# MSS_PCR2 register map
Vendor: Texas Instruments
Peripheral module from a debugger description file (folder awr2544).
Registers are 32-bit, read-write, no defined reset value unless marked. A register's access mark holds for its fields unless they carry their own. Offsets are as the file gives them; lines under a group give offsets from that group; [hi:lo] are bit positions; {n}, {i} and the like mark numbered series; 'fields as' and 'values as' point back to an identical list; <NAME> marks a mode.

## MSS_PCR2 (part 1 of 2)
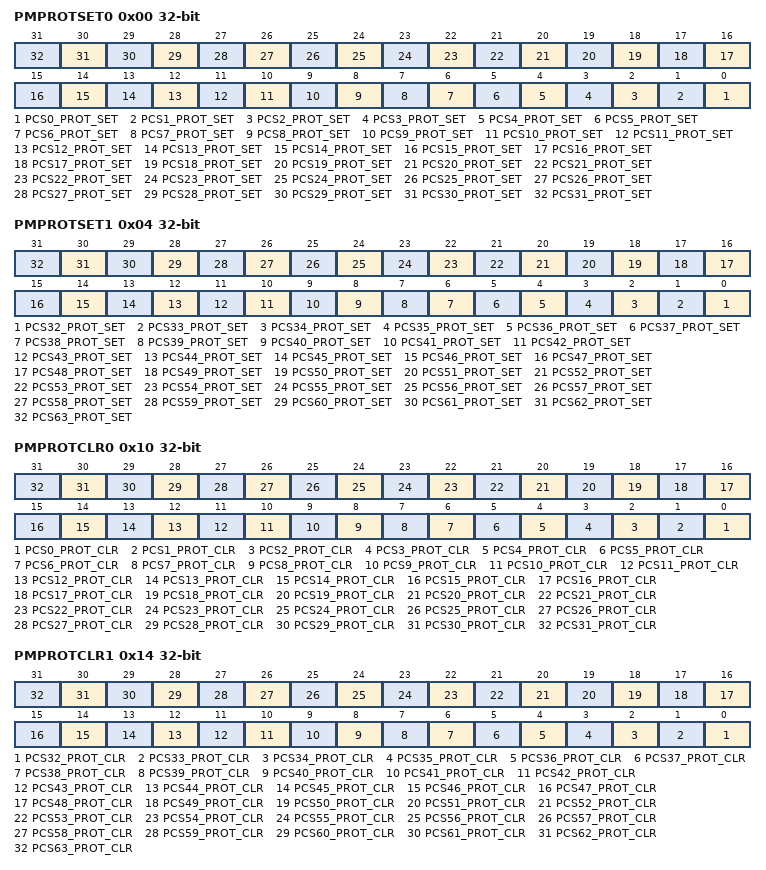
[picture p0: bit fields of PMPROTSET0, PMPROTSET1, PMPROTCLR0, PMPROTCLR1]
0x00 PMPROTSET0 — Set-only register to protect PCS frames 0 to 31
  [n] PCS{n}_PROT_SET (n=0..31) — Readable in user and privileged modes 1 = The corresponding peripheral memory frame can be written to only in privileged mode but can be read in both user and privileged modes. 0 = The corresponding peripheral memory frame can be written to and read from in both user and privileged modes. Writable only in privileged mode 1 = Sets the corresponding bit in PMPROTSET0 and PMPROTCLR0 registers 0 = Has no effect Only those bits which have a slave at the corresponding bit position are implemented. Hence, the size of this register is device dependent. Writes to unimplemented bits have no effect and reads yield 0.
0x04 PMPROTSET1 — Set-only register to protect PCS frames 32 to 63
  [n-32] PCS{n}_PROT_SET (n=32..63) — Readable in user and privileged modes 1 = The corresponding peripheral memory frame can be written to only in privileged mode but can be read in both user and privileged modes. 0 = The corresponding peripheral memory frame can be written to and read from in both user and privileged modes. Writable only in privileged mode 1 = Sets the corresponding bit in PMPROTSET1 and PMPROTCLR1 registers 0 = Has no effect
0x10 PMPROTCLR0 — Clear-only register to protect PCS frames 0 to 31
  [n] PCS{n}_PROT_CLR (n=0..31) — Readable in user and privileged modes 1 = The corresponding peripheral memory frame can be written to only in privileged mode but can be read in both user and privileged modes. 0 = The corresponding peripheral memory frame can be written to and read from in both user and privileged modes. Writable only in privileged mode 1 = Clears the corresponding bit in PMPROTCLR0 and PMPROTSET0 registers 0 = Has no effect
0x14 PMPROTCLR1 — Clear-only register to protect PCS frames 32 to 63
  [n-32] PCS{n}_PROT_CLR (n=32..63) — Readable in user and privileged modes 1 = The corresponding peripheral memory frame can be written to only in privileged mode but can be read in both user and privileged modes. 0 = The corresponding peripheral memory frame can be written to and read from in both user and privileged modes. Writable only in privileged mode 1 = Clears the corresponding bit in PMPROTCLR1 and PMPROTSET1 registers 0 = Has no effect
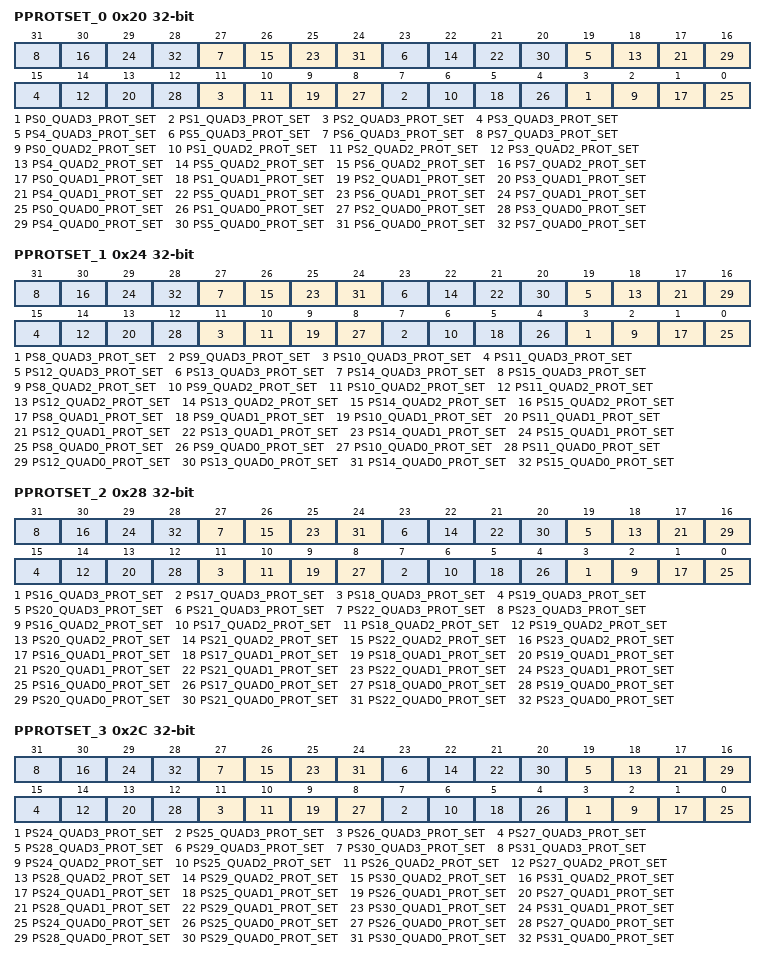
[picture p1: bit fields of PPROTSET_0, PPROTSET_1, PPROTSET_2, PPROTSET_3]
0x20 PPROTSET_0 — Set-only register to protect the 32 quadrants of PS0 to PS7
  [4n+3] PS{n}_QUAD3_PROT_SET (n=0..7) — Readable in both user and privileged modes. 1 = The quadrant ‘m’ of the peripheral frame ‘n’ can be written to only in privileged mode but can be read in both user and privileged modes. 0 = The corresponding peripheral memory frame can be written to and read from in both user and privileged modes. Writable only in privileged mode 1 = Sets the corresponding bit in PPROTSET0 and PPROTCLR0 registers 0 = Has no effect
  [4n+2] PS{n}_QUAD2_PROT_SET (n=0..7) — Readable in both user and privileged modes. 1 = The quadrant ‘m’ of the peripheral frame ‘n’ can be written to only in privileged mode but can be read in both user and privileged modes. 0 = The corresponding peripheral memory frame can be written to and read from in both user and privileged modes. Writable only in privileged mode 1 = Sets the corresponding bit in PPROTSET0 and PPROTCLR0 registers 0 = Has no effect
  [4n+1] PS{n}_QUAD1_PROT_SET (n=0..7) — Readable in both user and privileged modes. 1 = The quadrant ‘m’ of the peripheral frame ‘n’ can be written to only in privileged mode but can be read in both user and privileged modes. 0 = The corresponding peripheral memory frame can be written to and read from in both user and privileged modes. Writable only in privileged mode 1 = Sets the corresponding bit in PPROTSET0 and PPROTCLR0 registers 0 = Has no effect
  [4n] PS{n}_QUAD0_PROT_SET (n=0..7) — Readable in both user and privileged modes. 1 = The quadrant ‘m’ of the peripheral frame ‘n’ can be written to only in privileged mode but can be read in both user and privileged modes. 0 = The corresponding peripheral memory frame can be written to and read from in both user and privileged modes. Writable only in privileged mode 1 = Sets the corresponding bit in PPROTSET0 and PPROTCLR0 registers 0 = Has no effect
0x24 PPROTSET_1 — Set-only register to protect the 32 quadrants of PS8 to PS15
  [4n-29] PS{n}_QUAD3_PROT_SET (n=8..15) — Readable in both user and privileged modes. 1 = The quadrant ‘m’ of the peripheral frame ‘n’ can be written to only in privileged mode but can be read in both user and privileged modes. 0 = The corresponding peripheral memory frame can be written to and read from in both user and privileged modes. Writable only in privileged mode 1 = Sets the corresponding bit in PPROTSET1 and PPROTCLR1 registers 0 = Has no effect
  [4n-30] PS{n}_QUAD2_PROT_SET (n=8..15) — Readable in both user and privileged modes. 1 = The quadrant ‘m’ of the peripheral frame ‘n’ can be written to only in privileged mode but can be read in both user and privileged modes. 0 = The corresponding peripheral memory frame can be written to and read from in both user and privileged modes. Writable only in privileged mode 1 = Sets the corresponding bit in PPROTSET1 and PPROTCLR1 registers 0 = Has no effect
  [4n-31] PS{n}_QUAD1_PROT_SET (n=8..15) — Readable in both user and privileged modes. 1 = The quadrant ‘m’ of the peripheral frame ‘n’ can be written to only in privileged mode but can be read in both user and privileged modes. 0 = The corresponding peripheral memory frame can be written to and read from in both user and privileged modes. Writable only in privileged mode 1 = Sets the corresponding bit in PPROTSET1 and PPROTCLR1 registers 0 = Has no effect
  [4n-32] PS{n}_QUAD0_PROT_SET (n=8..15) — Readable in both user and privileged modes. 1 = The quadrant ‘m’ of the peripheral frame ‘n’ can be written to only in privileged mode but can be read in both user and privileged modes. 0 = The corresponding peripheral memory frame can be written to and read from in both user and privileged modes. Writable only in privileged mode 1 = Sets the corresponding bit in PPROTSET1 and PPROTCLR1 registers 0 = Has no effect
0x28 PPROTSET_2 — Set-only register to protect the 32 quadrants of PS16 to PS23
  [4n-61] PS{n}_QUAD3_PROT_SET (n=16..23) — Readable in both user and privileged modes. 1 = The quadrant ‘m’ of the peripheral frame ‘n’ can be written to only in privileged mode but can be read in both user and privileged modes. 0 = The corresponding peripheral memory frame can be written to and read from in both user and privileged modes. Writable only in privileged mode 1 = Sets the corresponding bit in PPROTSET2 and PPROTCLR2 registers 0 = Has no effect
  [4n-62] PS{n}_QUAD2_PROT_SET (n=16..23) — Readable in both user and privileged modes. 1 = The quadrant ‘m’ of the peripheral frame ‘n’ can be written to only in privileged mode but can be read in both user and privileged modes. 0 = The corresponding peripheral memory frame can be written to and read from in both user and privileged modes. Writable only in privileged mode 1 = Sets the corresponding bit in PPROTSET2 and PPROTCLR2 registers 0 = Has no effect
  [4n-63] PS{n}_QUAD1_PROT_SET (n=16..23) — Readable in both user and privileged modes. 1 = The quadrant ‘m’ of the peripheral frame ‘n’ can be written to only in privileged mode but can be read in both user and privileged modes. 0 = The corresponding peripheral memory frame can be written to and read from in both user and privileged modes. Writable only in privileged mode 1 = Sets the corresponding bit in PPROTSET2 and PPROTCLR2 registers 0 = Has no effect
  [4n-64] PS{n}_QUAD0_PROT_SET (n=16..23) — Readable in both user and privileged modes. 1 = The quadrant ‘m’ of the peripheral frame ‘n’ can be written to only in privileged mode but can be read in both user and privileged modes. 0 = The corresponding peripheral memory frame can be written to and read from in both user and privileged modes. Writable only in privileged mode 1 = Sets the corresponding bit in PPROTSET2 and PPROTCLR2 registers 0 = Has no effect
0x2C PPROTSET_3 — Set-only register to protect the 32 quadrants of PS24 to PS31
  [4n-93] PS{n}_QUAD3_PROT_SET (n=24..31) — Readable in both user and privileged modes. 1 = The quadrant ‘m’ of the peripheral frame ‘n’ can be written to only in privileged mode but can be read in both user and privileged modes. 0 = The corresponding peripheral memory frame can be written to and read from in both user and privileged modes. Writable only in privileged mode 1 = Sets the corresponding bit in PPROTSET3 and PPROTCLR3 registers 0 = Has no effect
  [4n-94] PS{n}_QUAD2_PROT_SET (n=24..31) — Readable in both user and privileged modes. 1 = The quadrant ‘m’ of the peripheral frame ‘n’ can be written to only in privileged mode but can be read in both user and privileged modes. 0 = The corresponding peripheral memory frame can be written to and read from in both user and privileged modes. Writable only in privileged mode 1 = Sets the corresponding bit in PPROTSET3 and PPROTCLR3 registers 0 = Has no effect
  [4n-95] PS{n}_QUAD1_PROT_SET (n=24..31) — Readable in both user and privileged modes. 1 = The quadrant ‘m’ of the peripheral frame ‘n’ can be written to only in privileged mode but can be read in both user and privileged modes. 0 = The corresponding peripheral memory frame can be written to and read from in both user and privileged modes. Writable only in privileged mode 1 = Sets the corresponding bit in PPROTSET3 and PPROTCLR3 registers 0 = Has no effect
  [4n-96] PS{n}_QUAD0_PROT_SET (n=24..31) — Readable in both user and privileged modes. 1 = The quadrant ‘m’ of the peripheral frame ‘n’ can be written to only in privileged mode but can be read in both user and privileged modes. 0 = The corresponding peripheral memory frame can be written to and read from in both user and privileged modes. Writable only in privileged mode 1 = Sets the corresponding bit in PPROTSET3 and PPROTCLR3 registers 0 = Has no effect
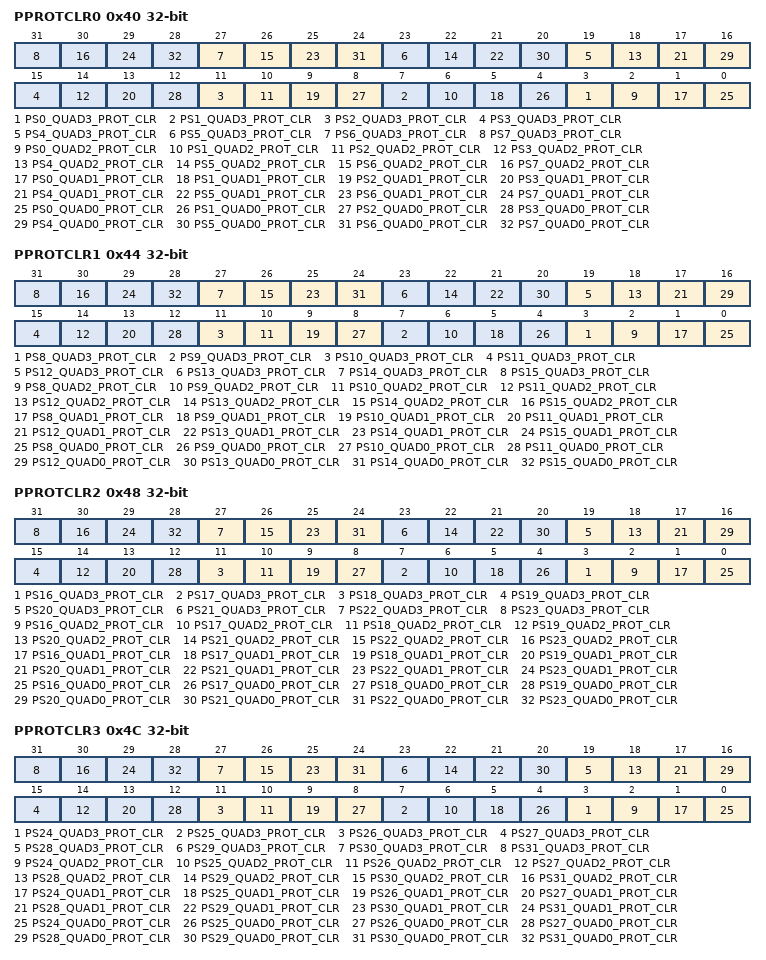
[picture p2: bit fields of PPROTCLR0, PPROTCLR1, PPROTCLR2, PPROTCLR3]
0x40 PPROTCLR0 — Clear-only register to protect the 32 quadrants of PS0 to PS7
  [4n+3] PS{n}_QUAD3_PROT_CLR (n=0..7) — Readable in both user and privileged modes. 1 = The quadrant ‘m’ of the peripheral frame ‘n’ can be written to only in privileged mode but can be read in both user and privileged modes. 0 = The corresponding peripheral memory frame can be written to and read from in both user and privileged modes. Writable only in privileged mode 1 = Clears the corresponding bit in PPROTSET0 and PPROTCLR0 registers 0 = Has no effect
  [4n+2] PS{n}_QUAD2_PROT_CLR (n=0..7) — Readable in both user and privileged modes. 1 = The quadrant ‘m’ of the peripheral frame ‘n’ can be written to only in privileged mode but can be read in both user and privileged modes. 0 = The corresponding peripheral memory frame can be written to and read from in both user and privileged modes. Writable only in privileged mode 1 = Clears the corresponding bit in PPROTSET0 and PPROTCLR0 registers 0 = Has no effect
  [4n+1] PS{n}_QUAD1_PROT_CLR (n=0..7) — Readable in both user and privileged modes. 1 = The quadrant ‘m’ of the peripheral frame ‘n’ can be written to only in privileged mode but can be read in both user and privileged modes. 0 = The corresponding peripheral memory frame can be written to and read from in both user and privileged modes. Writable only in privileged mode 1 = Clears the corresponding bit in PPROTSET0 and PPROTCLR0 registers 0 = Has no effect
  [4n] PS{n}_QUAD0_PROT_CLR (n=0..7) — Readable in both user and privileged modes. 1 = The quadrant ‘m’ of the peripheral frame ‘n’ can be written to only in privileged mode but can be read in both user and privileged modes. 0 = The corresponding peripheral memory frame can be written to and read from in both user and privileged modes. Writable only in privileged mode 1 = Clears the corresponding bit in PPROTSET0 and PPROTCLR0 registers 0 = Has no effect
0x44 PPROTCLR1 — Clear-only register to protect the 32 quadrants of PS8 to PS15
  [4n-29] PS{n}_QUAD3_PROT_CLR (n=8..15) — Readable in both user and privileged modes. 1 = The quadrant ‘m’ of the peripheral frame ‘n’ can be written to only in privileged mode but can be read in both user and privileged modes. 0 = The corresponding peripheral memory frame can be written to and read from in both user and privileged modes. Writable only in privileged mode 1 = Clears the corresponding bit in PPROTSET1 and PPROTCLR1 registers 0 = Has no effect
  [4n-30] PS{n}_QUAD2_PROT_CLR (n=8..15) — Readable in both user and privileged modes. 1 = The quadrant ‘m’ of the peripheral frame ‘n’ can be written to only in privileged mode but can be read in both user and privileged modes. 0 = The corresponding peripheral memory frame can be written to and read from in both user and privileged modes. Writable only in privileged mode 1 = Clears the corresponding bit in PPROTSET1 and PPROTCLR1 registers 0 = Has no effect
  [4n-31] PS{n}_QUAD1_PROT_CLR (n=8..15) — Readable in both user and privileged modes. 1 = The quadrant ‘m’ of the peripheral frame ‘n’ can be written to only in privileged mode but can be read in both user and privileged modes. 0 = The corresponding peripheral memory frame can be written to and read from in both user and privileged modes. Writable only in privileged mode 1 = Clears the corresponding bit in PPROTSET1 and PPROTCLR1 registers 0 = Has no effect
  [4n-32] PS{n}_QUAD0_PROT_CLR (n=8..15) — Readable in both user and privileged modes. 1 = The quadrant ‘m’ of the peripheral frame ‘n’ can be written to only in privileged mode but can be read in both user and privileged modes. 0 = The corresponding peripheral memory frame can be written to and read from in both user and privileged modes. Writable only in privileged mode 1 = Clears the corresponding bit in PPROTSET1 and PPROTCLR1 registers 0 = Has no effect
0x48 PPROTCLR2 — Clear-only register to protect the 32 quadrants of PS16 to PS23
  [4n-61] PS{n}_QUAD3_PROT_CLR (n=16..23) — Readable in both user and privileged modes. 1 = The quadrant ‘m’ of the peripheral frame ‘n’ can be written to only in privileged mode but can be read in both user and privileged modes. 0 = The corresponding peripheral memory frame can be written to and read from in both user and privileged modes. Writable only in privileged mode 1 = Clears the corresponding bit in PPROTSET2 and PPROTCLR2 registers 0 = Has no effect
  [4n-62] PS{n}_QUAD2_PROT_CLR (n=16..23) — Readable in both user and privileged modes. 1 = The quadrant ‘m’ of the peripheral frame ‘n’ can be written to only in privileged mode but can be read in both user and privileged modes. 0 = The corresponding peripheral memory frame can be written to and read from in both user and privileged modes. Writable only in privileged mode 1 = Clears the corresponding bit in PPROTSET2 and PPROTCLR2 registers 0 = Has no effect
  [4n-63] PS{n}_QUAD1_PROT_CLR (n=16..23) — Readable in both user and privileged modes. 1 = The quadrant ‘m’ of the peripheral frame ‘n’ can be written to only in privileged mode but can be read in both user and privileged modes. 0 = The corresponding peripheral memory frame can be written to and read from in both user and privileged modes. Writable only in privileged mode 1 = Clears the corresponding bit in PPROTSET2 and PPROTCLR2 registers 0 = Has no effect
  [4n-64] PS{n}_QUAD0_PROT_CLR (n=16..23) — Readable in both user and privileged modes. 1 = The quadrant ‘m’ of the peripheral frame ‘n’ can be written to only in privileged mode but can be read in both user and privileged modes. 0 = The corresponding peripheral memory frame can be written to and read from in both user and privileged modes. Writable only in privileged mode 1 = Clears the corresponding bit in PPROTSET2 and PPROTCLR2 registers 0 = Has no effect
0x4C PPROTCLR3 — Clear-only register to protect the 32 quadrants of PS24 to PS31
  [4n-93] PS{n}_QUAD3_PROT_CLR (n=24..31) — Readable in both user and privileged modes. 1 = The quadrant ‘m’ of the peripheral frame ‘n’ can be written to only in privileged mode but can be read in both user and privileged modes. 0 = The corresponding peripheral memory frame can be written to and read from in both user and privileged modes. Writable only in privileged mode 1 = Clears the corresponding bit in PPROTSET3 and PPROTCLR3 registers 0 = Has no effect
  [4n-94] PS{n}_QUAD2_PROT_CLR (n=24..31) — Readable in both user and privileged modes. 1 = The quadrant ‘m’ of the peripheral frame ‘n’ can be written to only in privileged mode but can be read in both user and privileged modes. 0 = The corresponding peripheral memory frame can be written to and read from in both user and privileged modes. Writable only in privileged mode 1 = Clears the corresponding bit in PPROTSET3 and PPROTCLR3 registers 0 = Has no effect
  [4n-95] PS{n}_QUAD1_PROT_CLR (n=24..31) — Readable in both user and privileged modes. 1 = The quadrant ‘m’ of the peripheral frame ‘n’ can be written to only in privileged mode but can be read in both user and privileged modes. 0 = The corresponding peripheral memory frame can be written to and read from in both user and privileged modes. Writable only in privileged mode 1 = Clears the corresponding bit in PPROTSET3 and PPROTCLR3 registers 0 = Has no effect
  [4n-96] PS{n}_QUAD0_PROT_CLR (n=24..31) — Readable in both user and privileged modes. 1 = The quadrant ‘m’ of the peripheral frame ‘n’ can be written to only in privileged mode but can be read in both user and privileged modes. 0 = The corresponding peripheral memory frame can be written to and read from in both user and privileged modes. Writable only in privileged mode 1 = Clears the corresponding bit in PPROTSET3 and PPROTCLR3 registers 0 = Has no effect
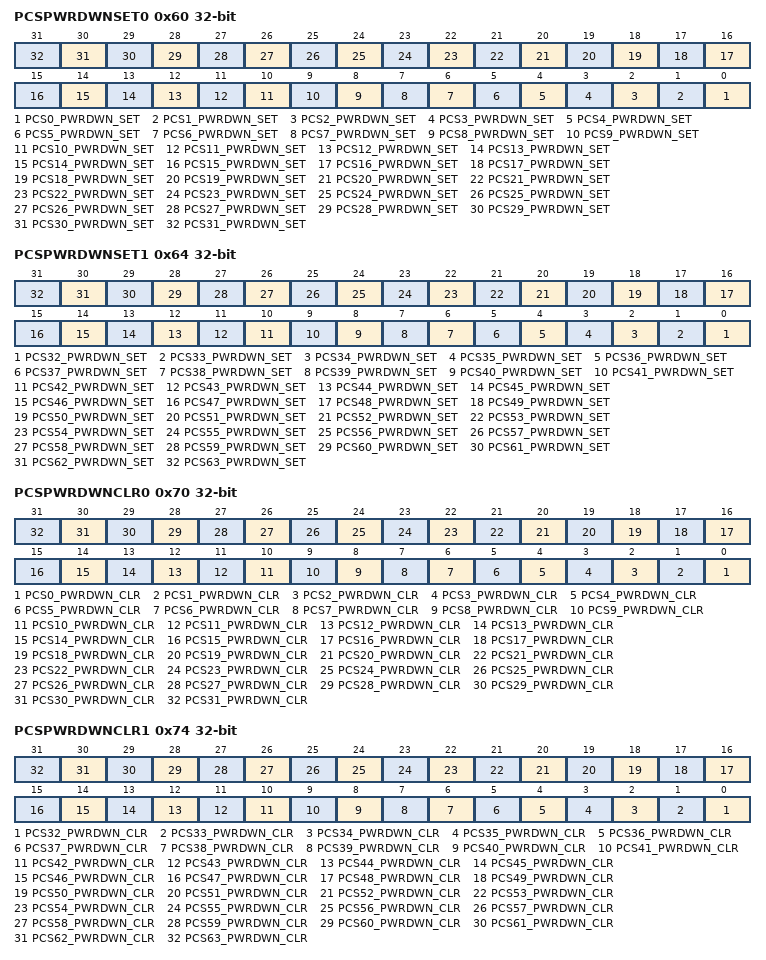
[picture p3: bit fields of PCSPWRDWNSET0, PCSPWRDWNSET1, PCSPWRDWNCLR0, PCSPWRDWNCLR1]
0x60 PCSPWRDWNSET0 — Set-only register to powerdown independent (non-shared) PCS frames 0 to 31
  [n] PCS{n}_PWRDWN_SET (n=0..31) — Readable in user and privileged modes 1 = The corresponding peripheral memory clock needs to be powered down. 0 = The corresponding peripheral memory clock is not to be powered down. Writable only in privileged mode 1 = Sets the corresponding bit in PCSPWRDWNSET0 and PCSPWRDWNCLR0 registers 0 = Has no effect
0x64 PCSPWRDWNSET1 — Set-only register to powerdown independent (non-shared) PCS frames 32 to 63
  [n-32] PCS{n}_PWRDWN_SET (n=32..63) — Readable in user and privileged modes 1 = The corresponding peripheral memory clock needs to be powered down. 0 = The corresponding peripheral memory clock is not to be powered down. Writable only in privileged mode 1 = Sets the corresponding bit in PCSPWRDWNSET1 and PCSPWRDWNCLR1 registers 0 = Has no effect
0x70 PCSPWRDWNCLR0 — Clear-only register to deassert powerdown bits of independent (non-shared) PCS frames 0 to 31
  [n] PCS{n}_PWRDWN_CLR (n=0..31) — Readable in user and privileged modes 1 = The corresponding peripheral memory clock needs to be powered down. 0 = The corresponding peripheral memory clock is not to be powered down. Writable only in privileged mode 1 = Clears the corresponding bit in PCSPWRDWNSET0 and PCSPWRDWNCLR0 registers 0 = Has no effect
0x74 PCSPWRDWNCLR1 — Clear-only register to deassert powerdown bits of independent (non-shared) PCS frames 32 to 63
  [n-32] PCS{n}_PWRDWN_CLR (n=32..63) — Readable in user and privileged modes 1 = The corresponding peripheral memory clock needs to be powered down. 0 = The corresponding peripheral memory clock is not to be powered down. Writable only in privileged mode 1 = Clears the corresponding bit in PCSPWRDWNSET1 and PCSPWRDWNCLR1 registers 0 = Has no effect
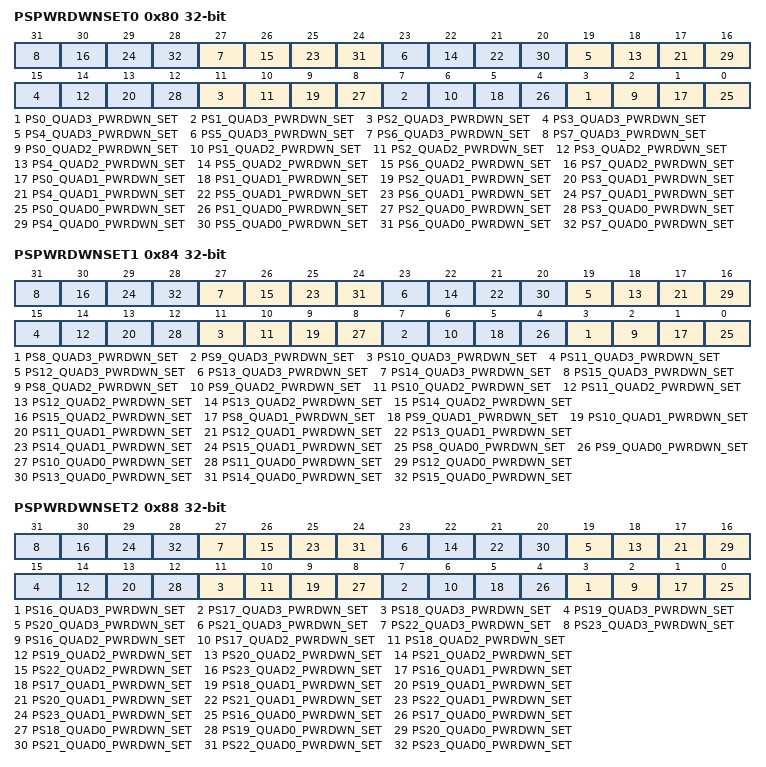
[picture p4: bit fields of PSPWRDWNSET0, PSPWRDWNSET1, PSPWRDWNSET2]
0x80 PSPWRDWNSET0 — Set-only register to powerdown the applicable peripherals in the 32 quadrants of PS0 to PS7
  [4n+3] PS{n}_QUAD3_PWRDWN_SET (n=0..7) — Readable in both user and privileged modes. 1 = The clock to the peripheral starting at quadrant ‘m’ of the peripheral frame ‘n’ needs to be powered down. 0 = The clock to the peripheral starting at quadrant ‘m’ of the peripheral frame ‘n’ needs to be powered up. Writable only in privileged mode 1 = Sets the corresponding bit in PSPWRDWNSET0 and PSPWRDWNCLR0 registers 0 = Has no effect
  [4n+2] PS{n}_QUAD2_PWRDWN_SET (n=0..7) — Readable in both user and privileged modes. 1 = The clock to the peripheral starting at quadrant ‘m’ of the peripheral frame ‘n’ needs to be powered down. 0 = The clock to the peripheral starting at quadrant ‘m’ of the peripheral frame ‘n’ needs to be powered up. Writable only in privileged mode 1 = Sets the corresponding bit in PSPWRDWNSET0 and PSPWRDWNCLR0 registers 0 = Has no effect
  [4n+1] PS{n}_QUAD1_PWRDWN_SET (n=0..7) — Readable in both user and privileged modes. 1 = The clock to the peripheral starting at quadrant ‘m’ of the peripheral frame ‘n’ needs to be powered down. 0 = The clock to the peripheral starting at quadrant ‘m’ of the peripheral frame ‘n’ needs to be powered up. Writable only in privileged mode 1 = Sets the corresponding bit in PSPWRDWNSET0 and PSPWRDWNCLR0 registers 0 = Has no effect
  [4n] PS{n}_QUAD0_PWRDWN_SET (n=0..7) — Readable in both user and privileged modes. 1 = The clock to the peripheral starting at quadrant ‘m’ of the peripheral frame ‘n’ needs to be powered down. 0 = The clock to the peripheral starting at quadrant ‘m’ of the peripheral frame ‘n’ needs to be powered up. Writable only in privileged mode 1 = Sets the corresponding bit in PSPWRDWNSET0 and PSPWRDWNCLR0 registers 0 = Has no effect
0x84 PSPWRDWNSET1 — Set-only register to powerdown the applicable peripherals in the 32 quadrants of PS8 to PS15
  [4n-29] PS{n}_QUAD3_PWRDWN_SET (n=8..15) — Readable in both user and privileged modes. 1 = The clock to the peripheral starting at quadrant ‘m’ of the peripheral frame ‘n’ needs to be powered down. 0 = The clock to the peripheral starting at quadrant ‘m’ of the peripheral frame ‘n’ needs to be powered up. Writable only in privileged mode 1 = Sets the corresponding bit in PSPWRDWNSET1 and PSPWRDWNCLR1 registers 0 = Has no effect
  [4n-30] PS{n}_QUAD2_PWRDWN_SET (n=8..15) — Readable in both user and privileged modes. 1 = The clock to the peripheral starting at quadrant ‘m’ of the peripheral frame ‘n’ needs to be powered down. 0 = The clock to the peripheral starting at quadrant ‘m’ of the peripheral frame ‘n’ needs to be powered up. Writable only in privileged mode 1 = Sets the corresponding bit in PSPWRDWNSET1 and PSPWRDWNCLR1 registers 0 = Has no effect
  [4n-31] PS{n}_QUAD1_PWRDWN_SET (n=8..15) — Readable in both user and privileged modes. 1 = The clock to the peripheral starting at quadrant ‘m’ of the peripheral frame ‘n’ needs to be powered down. 0 = The clock to the peripheral starting at quadrant ‘m’ of the peripheral frame ‘n’ needs to be powered up. Writable only in privileged mode 1 = Sets the corresponding bit in PSPWRDWNSET1 and PSPWRDWNCLR1 registers 0 = Has no effect
  [4n-32] PS{n}_QUAD0_PWRDWN_SET (n=8..15) — Readable in both user and privileged modes. 1 = The clock to the peripheral starting at quadrant ‘m’ of the peripheral frame ‘n’ needs to be powered down. 0 = The clock to the peripheral starting at quadrant ‘m’ of the peripheral frame ‘n’ needs to be powered up. Writable only in privileged mode 1 = Sets the corresponding bit in PSPWRDWNSET1 and PSPWRDWNCLR1 registers 0 = Has no effect
0x88 PSPWRDWNSET2 — Set-only register to powerdown the applicable peripherals in the 32 quadrants of PS16 to PS23
  [4n-61] PS{n}_QUAD3_PWRDWN_SET (n=16..23) — Readable in both user and privileged modes. 1 = The clock to the peripheral starting at quadrant ‘m’ of the peripheral frame ‘n’ needs to be powered down. 0 = The clock to the peripheral starting at quadrant ‘m’ of the peripheral frame ‘n’ needs to be powered up. Writable only in privileged mode 1 = Sets the corresponding bit in PSPWRDWNSET2 and PSPWRDWNCLR2 registers 0 = Has no effect
  [4n-62] PS{n}_QUAD2_PWRDWN_SET (n=16..23) — Readable in both user and privileged modes. 1 = The clock to the peripheral starting at quadrant ‘m’ of the peripheral frame ‘n’ needs to be powered down. 0 = The clock to the peripheral starting at quadrant ‘m’ of the peripheral frame ‘n’ needs to be powered up. Writable only in privileged mode 1 = Sets the corresponding bit in PSPWRDWNSET2 and PSPWRDWNCLR2 registers 0 = Has no effect
  [4n-63] PS{n}_QUAD1_PWRDWN_SET (n=16..23) — Readable in both user and privileged modes. 1 = The clock to the peripheral starting at quadrant ‘m’ of the peripheral frame ‘n’ needs to be powered down. 0 = The clock to the peripheral starting at quadrant ‘m’ of the peripheral frame ‘n’ needs to be powered up. Writable only in privileged mode 1 = Sets the corresponding bit in PSPWRDWNSET2 and PSPWRDWNCLR2 registers 0 = Has no effect
  [4n-64] PS{n}_QUAD0_PWRDWN_SET (n=16..23) — Readable in both user and privileged modes. 1 = The clock to the peripheral starting at quadrant ‘m’ of the peripheral frame ‘n’ needs to be powered down. 0 = The clock to the peripheral starting at quadrant ‘m’ of the peripheral frame ‘n’ needs to be powered up. Writable only in privileged mode 1 = Sets the corresponding bit in PSPWRDWNSET2 and PSPWRDWNCLR2 registers 0 = Has no effect
